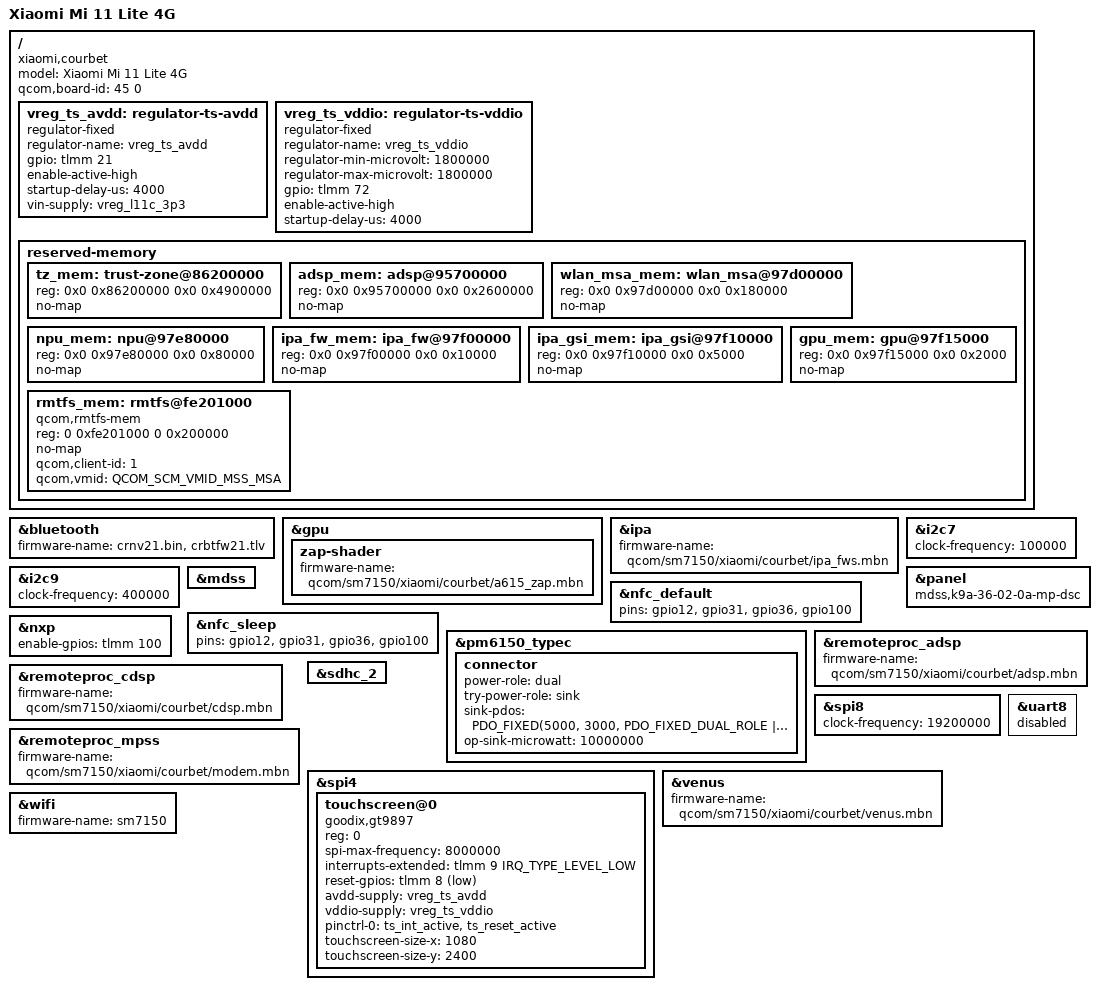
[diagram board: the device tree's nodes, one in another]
// SPDX-License-Identifier: BSD-3-Clause
/*
 * Copyright (c) 2024, Danila Tikhonov <danila@jiaxyga.com>
 */

/dts-v1/;

#include "sm7150-xiaomi-common.dtsi"

/delete-node/ &adsp_mem;
/delete-node/ &wlan_msa_mem;
/delete-node/ &npu_mem;
/delete-node/ &ipa_fw_mem;
/delete-node/ &ipa_gsi_mem;
/delete-node/ &gpu_mem;
/delete-node/ &tz_mem;

/ {
	model = "Xiaomi Mi 11 Lite 4G";
	compatible = "xiaomi,courbet", "qcom,sm7150";

	qcom,board-id = <45 0>;

	vreg_ts_avdd: regulator-ts-avdd {
		compatible = "regulator-fixed";
		regulator-name = "vreg_ts_avdd";
		gpio = <&tlmm 21 GPIO_ACTIVE_HIGH>;
		enable-active-high;
		startup-delay-us = <4000>;
		vin-supply = <&vreg_l11c_3p3>;
	};

	vreg_ts_vddio: regulator-ts-vddio {
		compatible = "regulator-fixed";
		regulator-name = "vreg_ts_vddio";
		regulator-min-microvolt = <1800000>;
		regulator-max-microvolt = <1800000>;
		gpio = <&tlmm 72 GPIO_ACTIVE_HIGH>;
		enable-active-high;
		startup-delay-us = <4000>;
	};

	reserved-memory {
		tz_mem: trust-zone@86200000 {
			reg = <0x0 0x86200000 0x0 0x4900000>;
			no-map;
		};

		adsp_mem: adsp@95700000 {
			reg = <0x0 0x95700000 0x0 0x2600000>;
			no-map;
		};

		wlan_msa_mem: wlan_msa@97d00000 {
			reg = <0x0 0x97d00000 0x0 0x180000>;
			no-map;
		};

		npu_mem: npu@97e80000 {
			reg = <0x0 0x97e80000 0x0 0x80000>;
			no-map;
		};

		ipa_fw_mem: ipa_fw@97f00000 {
			reg = <0x0 0x97f00000 0x0 0x10000>;
			no-map;
		};

		ipa_gsi_mem: ipa_gsi@97f10000 {
			reg = <0x0 0x97f10000 0x0 0x5000>;
			no-map;
		};

		gpu_mem: gpu@97f15000 {
			reg = <0x0 0x97f15000 0x0 0x2000>;
			no-map;
		};

		rmtfs_mem: rmtfs@fe201000 {
			compatible = "qcom,rmtfs-mem";
			reg = <0 0xfe201000 0 0x200000>;
			no-map;

			qcom,client-id = <1>;
			qcom,vmid = <QCOM_SCM_VMID_MSS_MSA>;
		};
	};
};

&bluetooth {
	firmware-name = "crnv21.bin", "crbtfw21.tlv";
};

&gpu {
	zap-shader {
		firmware-name = "qcom/sm7150/xiaomi/courbet/a615_zap.mbn";
	};
};

&ipa {
	firmware-name = "qcom/sm7150/xiaomi/courbet/ipa_fws.mbn";
};

&i2c7 {
	clock-frequency = <100000>;
	status = "okay";

	/* qcom,pm8008 (pmic) @ 8 */
	/* qcom,pm8008 (pmic) @ 9 */
	/* tfa,tfa98xx (speaker amplifier) @ 34 */
	/* tfa,tfa98xx (speaker amplifier) @ 35 */
	/* st,fts (ts) @ 49 */
	/* goodix,gt9886 (ts) @ 5d */
};

&i2c9 {
	clock-frequency = <400000>;
	status = "okay";

	/* qcom,fsa4480 (usb switcher) @ 42 */
	/* awinic,aw8624 (haptic) @ 5a */
	/* ti,bq25968 (charger) @ 66 */
};

&mdss {
	/delete-property/ resets;
};

&panel {
	compatible = "mdss,k9a-36-02-0a-mp-dsc";
};

&nfc_default {
	pins = "gpio12", "gpio31", "gpio36", "gpio100";
};

&nfc_sleep {
	pins = "gpio12", "gpio31", "gpio36", "gpio100";
};

&nxp {
	enable-gpios = <&tlmm 100 GPIO_ACTIVE_HIGH>;
};

&pm6150_typec {
	connector {
		power-role = "dual";
		try-power-role = "sink";

		sink-pdos = <PDO_FIXED(5000, 3000, PDO_FIXED_DUAL_ROLE |
			     PDO_FIXED_USB_COMM | PDO_FIXED_DATA_SWAP)>;
		op-sink-microwatt = <10000000>;
	};
};

&remoteproc_adsp {
	firmware-name = "qcom/sm7150/xiaomi/courbet/adsp.mbn";
};

&remoteproc_cdsp {
	firmware-name = "qcom/sm7150/xiaomi/courbet/cdsp.mbn";
};

&remoteproc_mpss {
	firmware-name = "qcom/sm7150/xiaomi/courbet/modem.mbn";
};

&sdhc_2 {
	status = "okay";
};

&spi4 {
	status = "okay";

	touchscreen@0 {
		compatible = "goodix,gt9897";
		reg = <0>;
		spi-max-frequency = <8000000>;

		interrupts-extended = <&tlmm 9 IRQ_TYPE_LEVEL_LOW>;
		reset-gpios = <&tlmm 8 GPIO_ACTIVE_LOW>;

		avdd-supply = <&vreg_ts_avdd>;
		vddio-supply = <&vreg_ts_vddio>;

		pinctrl-0 = <&ts_int_active &ts_reset_active>;
		pinctrl-names = "default";

		touchscreen-size-x = <1080>;
		touchscreen-size-y = <2400>;
	};
};

&spi8 {
	clock-frequency = <19200000>;
	status = "okay";

	/* ir-spi @ 0 */
};

&uart8 {
	status = "disabled";
};

&venus {
	firmware-name = "qcom/sm7150/xiaomi/courbet/venus.mbn";
};

&wifi {
	firmware-name = "sm7150";
};
